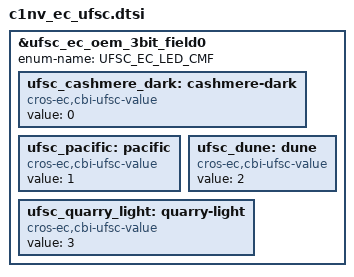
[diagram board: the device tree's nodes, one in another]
/* Copyright 2026 The ChromiumOS Authors
 * Use of this source code is governed by a BSD-style license that can be
 * found in the LICENSE file.
 */

#include <cros/cbi_ufsc_std_schema.dtsi>
#include <cros/cbi_ufsc_oem_schema.dtsi>

/* Auto-generated by generate_ufsc.py */

&ufsc_ec_oem_3bit_field0 {
	status = "okay";
	enum-name = "UFSC_EC_LED_CMF";

	ufsc_cashmere_dark: cashmere-dark {
		compatible = "cros-ec,cbi-ufsc-value";
		status = "okay";
		value = <0>;
	};
	ufsc_pacific: pacific {
		compatible = "cros-ec,cbi-ufsc-value";
		status = "okay";
		value = <1>;
	};
	ufsc_dune: dune {
		compatible = "cros-ec,cbi-ufsc-value";
		status = "okay";
		value = <2>;
	};
	ufsc_quarry_light: quarry-light {
		compatible = "cros-ec,cbi-ufsc-value";
		status = "okay";
		value = <3>;
	};
};

